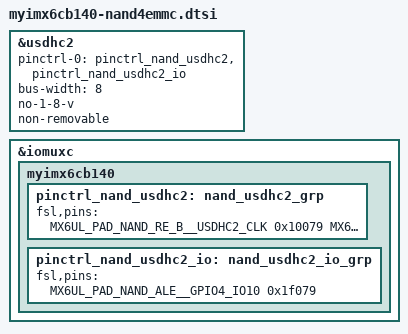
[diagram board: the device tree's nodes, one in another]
/*
 * MYZR Technology Co.,Ltd
 * http://www.myzr.com.cn
 * Tang Bin <tangb@myzr.com.cn>
 * 2018-10-18
 */

&usdhc2 {
	pinctrl-names = "default";
	pinctrl-0 = <&pinctrl_nand_usdhc2>, <&pinctrl_nand_usdhc2_io>;
	bus-width = <8>;
	no-1-8-v;
	non-removable;
	status = "okay";
};

&iomuxc {
	myimx6cb140 {
		pinctrl_nand_usdhc2: nand_usdhc2_grp {
			fsl,pins = <
				MX6UL_PAD_NAND_RE_B__USDHC2_CLK         0x10079
				MX6UL_PAD_NAND_WE_B__USDHC2_CMD     	0x1f079
				MX6UL_PAD_NAND_DATA00__USDHC2_DATA0 	0x1f079
				MX6UL_PAD_NAND_DATA01__USDHC2_DATA1 	0x1f079
				MX6UL_PAD_NAND_DATA02__USDHC2_DATA2 	0x1f079
				MX6UL_PAD_NAND_DATA03__USDHC2_DATA3 	0x1f079
				MX6UL_PAD_NAND_DATA04__USDHC2_DATA4 	0x1f079
				MX6UL_PAD_NAND_DATA05__USDHC2_DATA5 	0x1f079
				MX6UL_PAD_NAND_DATA06__USDHC2_DATA6 	0x1f079
				MX6UL_PAD_NAND_DATA07__USDHC2_DATA7 	0x1f079
			>;
		};
		
		pinctrl_nand_usdhc2_io: nand_usdhc2_io_grp {
			fsl,pins = <
				MX6UL_PAD_NAND_ALE__GPIO4_IO10          0x1f079
			>;
		};
	};
};
